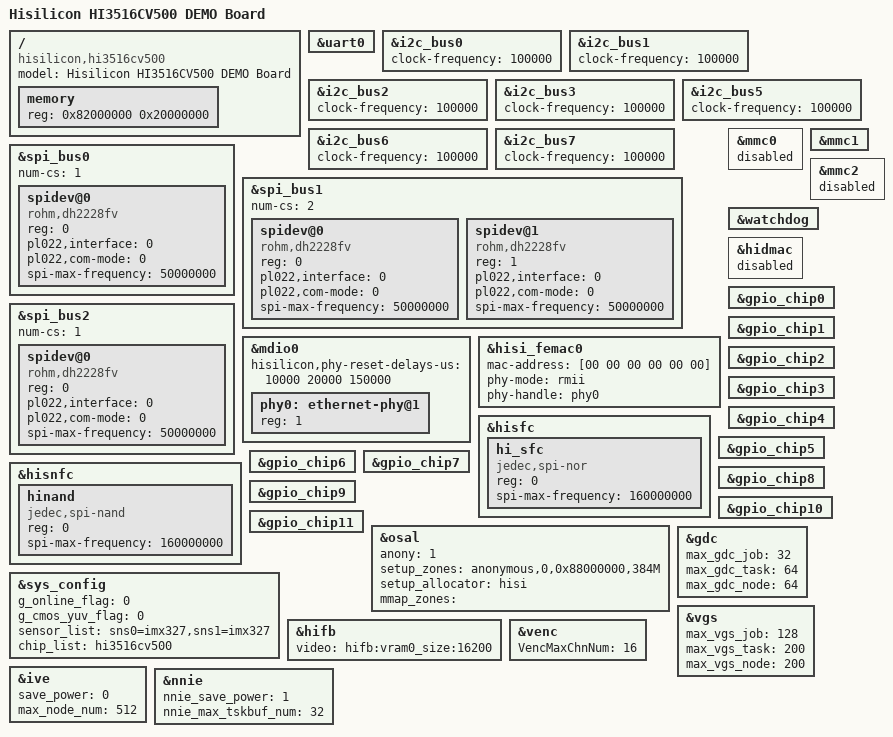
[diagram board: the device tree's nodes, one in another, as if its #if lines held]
/*
 * Copyright (c) 2013-2014 Linaro Ltd.
 * Copyright (c) 2015-2017 HiSilicon Technologies Co., Ltd.
 *
 * This program is free software; you can redistribute  it and/or modify it
 * under  the terms of  the GNU General  Public License as published by the
 * Free Software Foundation;  either version 2 of the  License, or (at your
 * option) any later version.
 *
 * This program is distributed in the hope that it will be useful,
 * but WITHOUT ANY WARRANTY; without even the implied warranty of
 * MERCHANTABILITY or FITNESS FOR A PARTICULAR PURPOSE. See the
 * GNU General Public License for more details.
 *
 * You should have received a copy of the GNU General Public License
 * along with this program.  If not, see <http://www.gnu.org/licenses/>.
 *
 */

/dts-v1/;
#include "hi3516cv500.dtsi"

/ {
	model = "Hisilicon HI3516CV500 DEMO Board";
	compatible = "hisilicon,hi3516cv500";

	memory {
		device_type = "memory";
		reg = <0x82000000 0x20000000>;
	};
};

&uart0 {
	status = "okay";
};
#ifndef CONFIG_ARCH_HISI_BVT_AMP
&i2c_bus0 {
    status = "okay";
    clock-frequency = <100000>;
};

&i2c_bus1 {
    status = "okay";
    clock-frequency = <100000>;
};

&i2c_bus2 {
    status = "okay";
    clock-frequency = <100000>;
};

&i2c_bus3 {
    status = "okay";
    clock-frequency = <100000>;
};

&i2c_bus5 {
    status = "okay";
    clock-frequency = <100000>;
};

&i2c_bus6 {
    status = "okay";
    clock-frequency = <100000>;
};

&i2c_bus7 {
    status = "okay";
    clock-frequency = <100000>;
};

&spi_bus0{
    status = "okay";
    num-cs = <1>;

    spidev@0 {
        compatible = "rohm,dh2228fv";
        reg = <0>;
        pl022,interface = <0>;
        pl022,com-mode = <0>;
        spi-max-frequency = <50000000>;
    };
};
&spi_bus1{
    status = "okay";
    num-cs = <2>;

    spidev@0 {
        compatible = "rohm,dh2228fv";
        reg = <0>;
        pl022,interface = <0>;
        pl022,com-mode = <0>;
        spi-max-frequency = <50000000>;
    };
    spidev@1 {
        compatible = "rohm,dh2228fv";
        reg = <1>;
        pl022,interface = <0>;
        pl022,com-mode = <0>;
        spi-max-frequency = <50000000>;
    };
};
&spi_bus2{
    status = "okay";
    num-cs = <1>;

    spidev@0 {
        compatible = "rohm,dh2228fv";
        reg = <0>;
        pl022,interface = <0>;
        pl022,com-mode = <0>;
        spi-max-frequency = <50000000>;
    };
};
#endif

&mdio0 {
	hisilicon,phy-reset-delays-us = <10000 20000 150000>;
	phy0: ethernet-phy@1 {
		reg = <1>;
	};
};

&hisi_femac0 {
	mac-address = [00 00 00 00 00 00];
	phy-mode = "rmii";
	phy-handle = <&phy0>;
	status = "okay";
};

&hisfc {
	hi_sfc {
		   compatible = "jedec,spi-nor";
		   reg = <0>;
		   spi-max-frequency = <160000000>;
	};
};

&hisnfc {
	hinand {
		   compatible = "jedec,spi-nand";
		   reg = <0>;
		   spi-max-frequency = <160000000>;
	};
};

&mmc0 {
#ifdef CONFIG_MTD
	status = "disabled";
#else
	status = "okay";
#endif
};

&mmc1 {
	status = "okay";
};

&mmc2 {
	status = "disabled";
};

&watchdog {
        status = "okay";
};

&hidmac {
	status = "disabled";
};

&gpio_chip0 {
	status = "okay";
};

&gpio_chip1 {
	status = "okay";
};

&gpio_chip2 {
	status = "okay";
};

&gpio_chip3 {
	status = "okay";
};

&gpio_chip4 {
	status = "okay";
};

&gpio_chip5 {
	status = "okay";
};

&gpio_chip6 {
	status = "okay";
};

&gpio_chip7 {
	status = "okay";
};

&gpio_chip8 {
	status = "okay";
};

&gpio_chip9 {
	status = "okay";
};

&gpio_chip10 {
	status = "okay";
};

&gpio_chip11 {
	status = "okay";
};

&osal {
        /*module param*/
        anony = <1>;
        setup_zones = "anonymous,0,0x88000000,384M";
        setup_allocator = "hisi";
	mmap_zones="";
};

&sys_config {
	/*module param*/
        g_online_flag = <0>;
	g_cmos_yuv_flag = <0>;
        sensor_list = "sns0=imx327,sns1=imx327";
        chip_list = "hi3516cv500";
};

&gdc {
        /*module param*/
        max_gdc_job = <32>;
        max_gdc_task = <64>;
        max_gdc_node = <64>;
};

&vgs {
        /*module param*/
        max_vgs_job = <128>;
        max_vgs_task = <200>;
        max_vgs_node = <200>;
};

&hifb {
        /*module param*/
        video = "hifb:vram0_size:16200";
};

&venc {
        /*module param*/
        VencMaxChnNum = <16>;
};

&ive {
        /*module param*/
        save_power = /bits/ 8  <0>;
	max_node_num = /bits/ 16 <512>;
};

&nnie {
        /*module param*/
        nnie_save_power = /bits/ 8  <1>;
        nnie_max_tskbuf_num = /bits/ 16 <32>;
};

